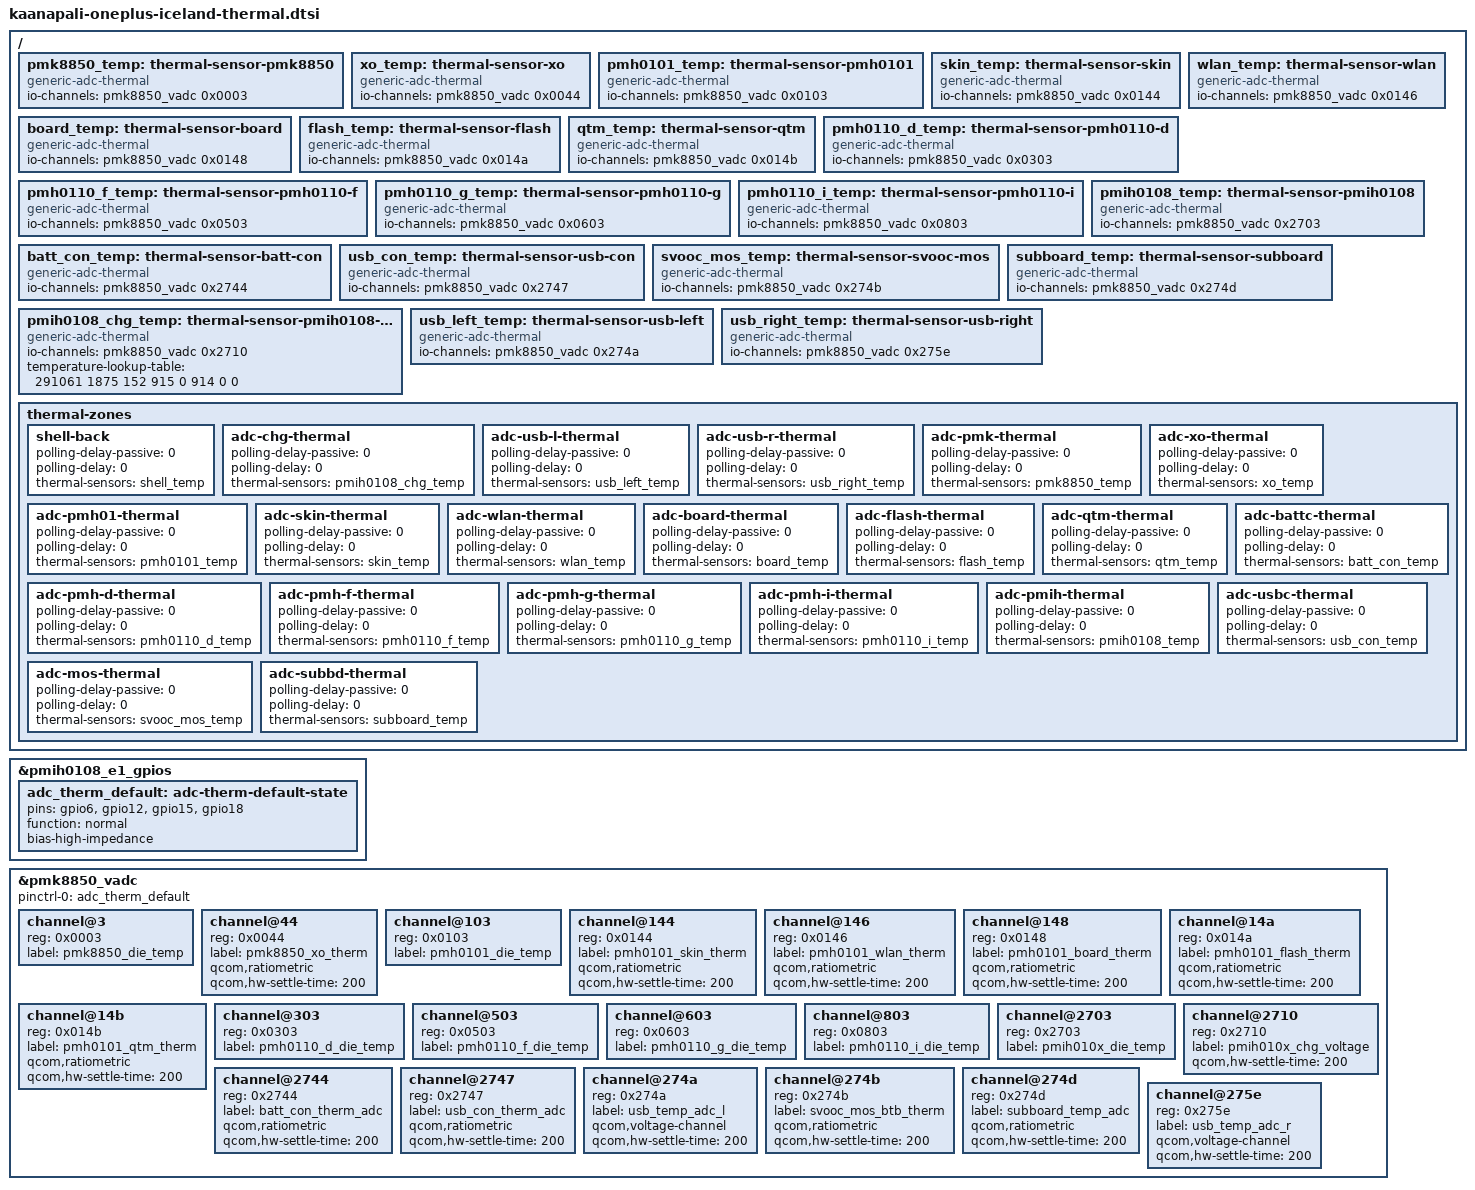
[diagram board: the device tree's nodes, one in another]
// SPDX-License-Identifier: BSD-3-Clause

/*
 * Iceland ADC temperature channels verified on hardware. The ADC driver
 * returns milliCelsius for temperature inputs. USB thermistors use the stock
 * board voltage-to-temperature table through generic-adc-thermal.
 * These zones provide on-demand readings only; they do not implement thermal
 * protection, threshold interrupts or periodic monitoring. The shell-back
 * zone is the estimator defined in the fast charging dtsi.
 */

/ {
	pmk8850_temp: thermal-sensor-pmk8850 {
		compatible = "generic-adc-thermal";
		io-channels = <&pmk8850_vadc 0x0003>;
		io-channel-names = "sensor-channel";
		#thermal-sensor-cells = <0>;
	};

	xo_temp: thermal-sensor-xo {
		compatible = "generic-adc-thermal";
		io-channels = <&pmk8850_vadc 0x0044>;
		io-channel-names = "sensor-channel";
		#thermal-sensor-cells = <0>;
	};

	pmh0101_temp: thermal-sensor-pmh0101 {
		compatible = "generic-adc-thermal";
		io-channels = <&pmk8850_vadc 0x0103>;
		io-channel-names = "sensor-channel";
		#thermal-sensor-cells = <0>;
	};

	skin_temp: thermal-sensor-skin {
		compatible = "generic-adc-thermal";
		io-channels = <&pmk8850_vadc 0x0144>;
		io-channel-names = "sensor-channel";
		#thermal-sensor-cells = <0>;
	};

	wlan_temp: thermal-sensor-wlan {
		compatible = "generic-adc-thermal";
		io-channels = <&pmk8850_vadc 0x0146>;
		io-channel-names = "sensor-channel";
		#thermal-sensor-cells = <0>;
	};

	board_temp: thermal-sensor-board {
		compatible = "generic-adc-thermal";
		io-channels = <&pmk8850_vadc 0x0148>;
		io-channel-names = "sensor-channel";
		#thermal-sensor-cells = <0>;
	};

	flash_temp: thermal-sensor-flash {
		compatible = "generic-adc-thermal";
		io-channels = <&pmk8850_vadc 0x014a>;
		io-channel-names = "sensor-channel";
		#thermal-sensor-cells = <0>;
	};

	qtm_temp: thermal-sensor-qtm {
		compatible = "generic-adc-thermal";
		io-channels = <&pmk8850_vadc 0x014b>;
		io-channel-names = "sensor-channel";
		#thermal-sensor-cells = <0>;
	};

	pmh0110_d_temp: thermal-sensor-pmh0110-d {
		compatible = "generic-adc-thermal";
		io-channels = <&pmk8850_vadc 0x0303>;
		io-channel-names = "sensor-channel";
		#thermal-sensor-cells = <0>;
	};

	pmh0110_f_temp: thermal-sensor-pmh0110-f {
		compatible = "generic-adc-thermal";
		io-channels = <&pmk8850_vadc 0x0503>;
		io-channel-names = "sensor-channel";
		#thermal-sensor-cells = <0>;
	};

	pmh0110_g_temp: thermal-sensor-pmh0110-g {
		compatible = "generic-adc-thermal";
		io-channels = <&pmk8850_vadc 0x0603>;
		io-channel-names = "sensor-channel";
		#thermal-sensor-cells = <0>;
	};

	pmh0110_i_temp: thermal-sensor-pmh0110-i {
		compatible = "generic-adc-thermal";
		io-channels = <&pmk8850_vadc 0x0803>;
		io-channel-names = "sensor-channel";
		#thermal-sensor-cells = <0>;
	};

	pmih0108_temp: thermal-sensor-pmih0108 {
		compatible = "generic-adc-thermal";
		io-channels = <&pmk8850_vadc 0x2703>;
		io-channel-names = "sensor-channel";
		#thermal-sensor-cells = <0>;
	};

	batt_con_temp: thermal-sensor-batt-con {
		compatible = "generic-adc-thermal";
		io-channels = <&pmk8850_vadc 0x2744>;
		io-channel-names = "sensor-channel";
		#thermal-sensor-cells = <0>;
	};

	usb_con_temp: thermal-sensor-usb-con {
		compatible = "generic-adc-thermal";
		io-channels = <&pmk8850_vadc 0x2747>;
		io-channel-names = "sensor-channel";
		#thermal-sensor-cells = <0>;
	};

	svooc_mos_temp: thermal-sensor-svooc-mos {
		compatible = "generic-adc-thermal";
		io-channels = <&pmk8850_vadc 0x274b>;
		io-channel-names = "sensor-channel";
		#thermal-sensor-cells = <0>;
	};

	subboard_temp: thermal-sensor-subboard {
		compatible = "generic-adc-thermal";
		io-channels = <&pmk8850_vadc 0x274d>;
		io-channel-names = "sensor-channel";
		#thermal-sensor-cells = <0>;
	};

	pmih0108_chg_temp: thermal-sensor-pmih0108-charger {
		compatible = "generic-adc-thermal";
		io-channels = <&pmk8850_vadc 0x2710>;
		io-channel-names = "sensor-channel";
		#thermal-sensor-cells = <0>;

		/* PM7: max(0, V(mV) / 3.3 - 277.12), output in mC. */
		temperature-lookup-table = <
			291061 1875
			152 915
			0 914
			0 0
		>;
	};

	usb_left_temp: thermal-sensor-usb-left {
		compatible = "generic-adc-thermal";
		io-channels = <&pmk8850_vadc 0x274a>;
		io-channel-names = "sensor-channel";
		#thermal-sensor-cells = <0>;

		#include "kaanapali-oneplus-iceland-usb-thermistor.dtsi"
	};

	usb_right_temp: thermal-sensor-usb-right {
		compatible = "generic-adc-thermal";
		io-channels = <&pmk8850_vadc 0x275e>;
		io-channel-names = "sensor-channel";
		#thermal-sensor-cells = <0>;

		#include "kaanapali-oneplus-iceland-usb-thermistor.dtsi"
	};

	thermal-zones {
		shell-back {
			polling-delay-passive = <0>;
			polling-delay = <0>;
			thermal-sensors = <&shell_temp>;
		};

		adc-chg-thermal {
			polling-delay-passive = <0>;
			polling-delay = <0>;
			thermal-sensors = <&pmih0108_chg_temp>;
		};

		adc-usb-l-thermal {
			polling-delay-passive = <0>;
			polling-delay = <0>;
			thermal-sensors = <&usb_left_temp>;
		};

		adc-usb-r-thermal {
			polling-delay-passive = <0>;
			polling-delay = <0>;
			thermal-sensors = <&usb_right_temp>;
		};

		adc-pmk-thermal {
			polling-delay-passive = <0>;
			polling-delay = <0>;
			thermal-sensors = <&pmk8850_temp>;
		};

		adc-xo-thermal {
			polling-delay-passive = <0>;
			polling-delay = <0>;
			thermal-sensors = <&xo_temp>;
		};

		adc-pmh01-thermal {
			polling-delay-passive = <0>;
			polling-delay = <0>;
			thermal-sensors = <&pmh0101_temp>;
		};

		adc-skin-thermal {
			polling-delay-passive = <0>;
			polling-delay = <0>;
			thermal-sensors = <&skin_temp>;
		};

		adc-wlan-thermal {
			polling-delay-passive = <0>;
			polling-delay = <0>;
			thermal-sensors = <&wlan_temp>;
		};

		adc-board-thermal {
			polling-delay-passive = <0>;
			polling-delay = <0>;
			thermal-sensors = <&board_temp>;
		};

		adc-flash-thermal {
			polling-delay-passive = <0>;
			polling-delay = <0>;
			thermal-sensors = <&flash_temp>;
		};

		adc-qtm-thermal {
			polling-delay-passive = <0>;
			polling-delay = <0>;
			thermal-sensors = <&qtm_temp>;
		};

		adc-pmh-d-thermal {
			polling-delay-passive = <0>;
			polling-delay = <0>;
			thermal-sensors = <&pmh0110_d_temp>;
		};

		adc-pmh-f-thermal {
			polling-delay-passive = <0>;
			polling-delay = <0>;
			thermal-sensors = <&pmh0110_f_temp>;
		};

		adc-pmh-g-thermal {
			polling-delay-passive = <0>;
			polling-delay = <0>;
			thermal-sensors = <&pmh0110_g_temp>;
		};

		adc-pmh-i-thermal {
			polling-delay-passive = <0>;
			polling-delay = <0>;
			thermal-sensors = <&pmh0110_i_temp>;
		};

		adc-pmih-thermal {
			polling-delay-passive = <0>;
			polling-delay = <0>;
			thermal-sensors = <&pmih0108_temp>;
		};

		adc-battc-thermal {
			polling-delay-passive = <0>;
			polling-delay = <0>;
			thermal-sensors = <&batt_con_temp>;
		};

		adc-usbc-thermal {
			polling-delay-passive = <0>;
			polling-delay = <0>;
			thermal-sensors = <&usb_con_temp>;
		};

		adc-mos-thermal {
			polling-delay-passive = <0>;
			polling-delay = <0>;
			thermal-sensors = <&svooc_mos_temp>;
		};

		adc-subbd-thermal {
			polling-delay-passive = <0>;
			polling-delay = <0>;
			thermal-sensors = <&subboard_temp>;
		};
	};
};

&pmih0108_e1_gpios {
	adc_therm_default: adc-therm-default-state {
		/* USB left/right, subboard and SVOOC MOS thermistors. */
		pins = "gpio6", "gpio12", "gpio15", "gpio18";
		function = "normal";
		bias-high-impedance;
	};
};

&pmk8850_vadc {
	pinctrl-0 = <&adc_therm_default>;
	pinctrl-names = "default";

	status = "okay";

	channel@3 {
		reg = <0x0003>;
		label = "pmk8850_die_temp";
	};

	channel@44 {
		reg = <0x0044>;
		label = "pmk8850_xo_therm";
		qcom,ratiometric;
		qcom,hw-settle-time = <200>;
	};

	channel@103 {
		reg = <0x0103>;
		label = "pmh0101_die_temp";
	};

	channel@144 {
		reg = <0x0144>;
		label = "pmh0101_skin_therm";
		qcom,ratiometric;
		qcom,hw-settle-time = <200>;
	};

	channel@146 {
		reg = <0x0146>;
		label = "pmh0101_wlan_therm";
		qcom,ratiometric;
		qcom,hw-settle-time = <200>;
	};

	channel@148 {
		reg = <0x0148>;
		label = "pmh0101_board_therm";
		qcom,ratiometric;
		qcom,hw-settle-time = <200>;
	};

	channel@14a {
		reg = <0x014a>;
		label = "pmh0101_flash_therm";
		qcom,ratiometric;
		qcom,hw-settle-time = <200>;
	};

	channel@14b {
		reg = <0x014b>;
		label = "pmh0101_qtm_therm";
		qcom,ratiometric;
		qcom,hw-settle-time = <200>;
	};

	channel@303 {
		reg = <0x0303>;
		label = "pmh0110_d_die_temp";
	};

	channel@503 {
		reg = <0x0503>;
		label = "pmh0110_f_die_temp";
	};

	channel@603 {
		reg = <0x0603>;
		label = "pmh0110_g_die_temp";
	};

	channel@803 {
		reg = <0x0803>;
		label = "pmh0110_i_die_temp";
	};

	channel@2703 {
		reg = <0x2703>;
		label = "pmih010x_die_temp";
	};

	channel@2710 {
		reg = <0x2710>;
		label = "pmih010x_chg_voltage";
		qcom,hw-settle-time = <200>;
	};

	/* Channel 0x2718 returned the -60 C endpoint; leave it unconfigured. */

	channel@2744 {
		reg = <0x2744>;
		label = "batt_con_therm_adc";
		qcom,ratiometric;
		qcom,hw-settle-time = <200>;
	};

	channel@2747 {
		reg = <0x2747>;
		label = "usb_con_therm_adc";
		qcom,ratiometric;
		qcom,hw-settle-time = <200>;
	};

	channel@274a {
		reg = <0x274a>;
		label = "usb_temp_adc_l";
		qcom,voltage-channel;
		qcom,hw-settle-time = <200>;
	};

	channel@274b {
		reg = <0x274b>;
		label = "svooc_mos_btb_therm";
		qcom,ratiometric;
		qcom,hw-settle-time = <200>;
	};

	channel@274d {
		reg = <0x274d>;
		label = "subboard_temp_adc";
		qcom,ratiometric;
		qcom,hw-settle-time = <200>;
	};

	channel@275e {
		reg = <0x275e>;
		label = "usb_temp_adc_r";
		qcom,voltage-channel;
		qcom,hw-settle-time = <200>;
	};
};
